# f29h85x_flash_cmd_regs_flc2 register map
Vendor: Texas Instruments
Peripheral module from a debugger description file (folder C29).
Registers are 32-bit, read-write, no defined reset value unless marked. A register's access mark holds for its fields unless they carry their own. Offsets are as the file gives them; lines under a group give offsets from that group; [hi:lo] are bit positions; {n}, {i} and the like mark numbered series; 'fields as' and 'values as' point back to an identical list; <NAME> marks a mode.

## FLASH_CMD_REGS_FLC2 — FLASH CMD Registers
0x00 IPSTANDARD group
  0x20 IIDX ro — Interrupt Index Register
    [0] STAT
  0xE0 EVT_MODE ro — Event Mode
    [1:0] INT0_CFG
0x100 IPSPECIFIC group
  0xD0 CMDWEPROTA — Command Write Erase Protect A Register
    [31:0] VAL
  0xD4 CMDWEPROTB — Command Write Erase Protect B Register
    [27:0] VAL
  0x110 CMDWEPROTNM — Command Write Erase Protect Non-Main Register
    [1:0] VAL
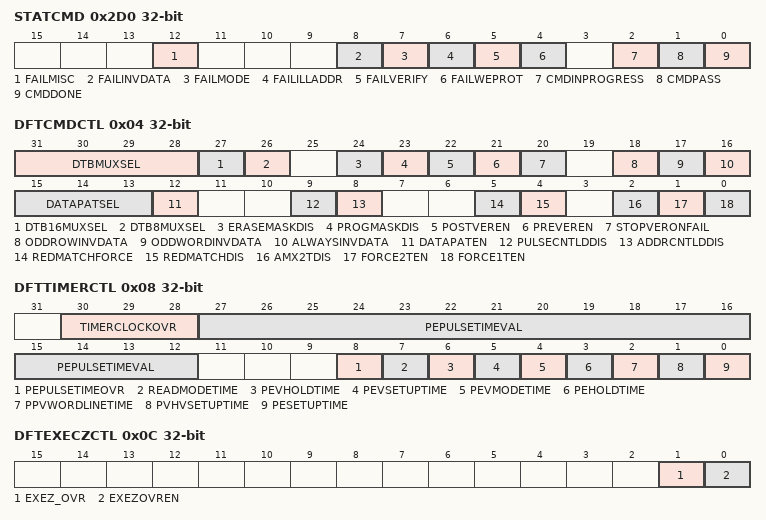
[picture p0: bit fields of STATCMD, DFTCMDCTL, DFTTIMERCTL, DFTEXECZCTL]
  0x2D0 STATCMD ro — Command Status Register
    [12] FAILMISC, [8] FAILINVDATA, [7] FAILMODE, [6] FAILILLADDR, [5] FAILVERIFY, [4] FAILWEPROT, [2] CMDINPROGRESS, [1] CMDPASS, [0] CMDDONE
0x400 EXT_EVT group
  0x80 CPU_CONNECT_0 — CPU Connect
    [1] CPUSS0_CONN
0x500 LMGMT_DFT_ATONLY group
  0x00 DFTEN — DFT Enable Register
    [0] ENABLE
  0x04 DFTCMDCTL — DFT Command Control Register
    [31:28] DTBMUXSEL, [27] DTB16MUXSEL, [26] DTB8MUXSEL, [24] ERASEMASKDIS, [23] PROGMASKDIS, [22] POSTVEREN, [21] PREVEREN, [20] STOPVERONFAIL, [18] ODDROWINVDATA, [17] ODDWORDINVDATA, [16] ALWAYSINVDATA, [15:13] DATAPATSEL, [12] DATAPATEN, [9] PULSECNTLDDIS, [8] ADDRCNTLDDIS, [5] REDMATCHFORCE, [4] REDMATCHDIS, [2] AMX2TDIS, [1] FORCE2TEN, [0] FORCE1TEN
  0x08 DFTTIMERCTL — DFT Timer Control Register
    [30:28] TIMERCLOCKOVR, [27:12] PEPULSETIMEVAL, [8] PEPULSETIMEOVR, [7] READMODETIME, [6] PEVHOLDTIME, [5] PEVSETUPTIME, [4] PEVMODETIME, [3] PEHOLDTIME, [2] PPVWORDLINETIME, [1] PVHVSETUPTIME, [0] PESETUPTIME
  0x0C DFTEXECZCTL — Flash Wrapper State EXECUTEZ Control Register
    [1] EXEZ_OVR, [0] EXEZOVREN
  0x10 DFTPCLKTESTCTL — DFT Pump Clock Test Control Register
    [0] ENABLE
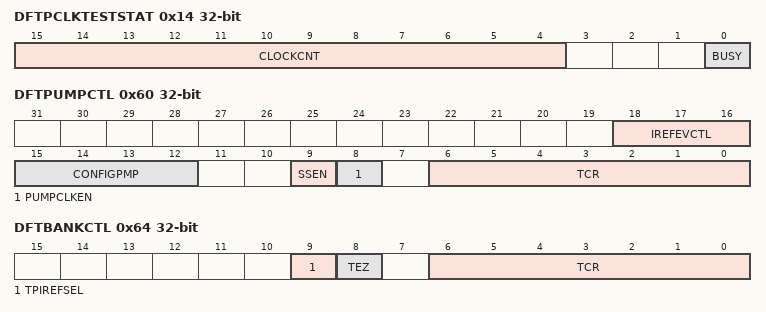
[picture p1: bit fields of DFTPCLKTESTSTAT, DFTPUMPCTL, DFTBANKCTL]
  0x14 DFTPCLKTESTSTAT ro — DFT Pump Clock Test Status Register
    [15:4] CLOCKCNT, [0] BUSY
  {0x40+4j} DFTDATARED{j} (j=0..7) — DFT Data Register Redundant {j}
    [3:0] VAL
  0x60 DFTPUMPCTL — DFT Pump Control Register
    [18:16] IREFEVCTL, [15:12] CONFIGPMP, [9] SSEN, [8] PUMPCLKEN, [6:0] TCR
  0x64 DFTBANKCTL — DFT Bank Control Register
    [9] TPIREFSEL, [8] TEZ, [6:0] TCR
